# S32K116_M0P register map
Vendor: NXP Semiconductors; File version: 1.1
CPU: CM0PLUS r0p0, little endian, MPU, FPU, VTOR, 4 interrupt priority bits
Registers are 32-bit, read-write, reset 0x0 unless marked. A register's access mark holds for its fields unless they carry their own. Offsets are from the block's base; [hi:lo] are bit positions; {n}, {i} and the like mark numbered series; 'fields as' and 'values as' point back to an identical list.

## PMC
Base 0x4007D000
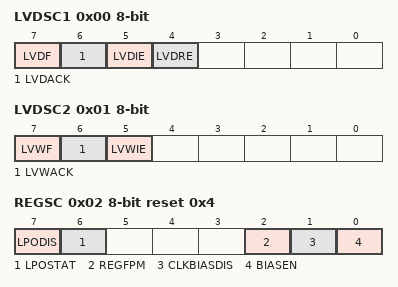
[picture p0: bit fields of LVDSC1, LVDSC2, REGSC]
0x00 LVDSC1 8-bit (reset mask 0xEF) — Low Voltage Detect Status and Control 1 Register
  [7] LVDF ro — Low Voltage Detect Flag
    0=Low-voltage event not detected; 1=Low-voltage event detected
  [6] LVDACK wo — Low Voltage Detect Acknowledge
  [5] LVDIE — Low Voltage Detect Interrupt Enable
    0=Hardware interrupt disabled (use polling); 1=Request a hardware interrupt when LVDF = 1
  [4] LVDRE — Low Voltage Detect Reset Enable
    0=No system resets on low voltage detect events; 1=If the supply voltage falls below VLVD, a system reset will be generated
0x01 LVDSC2 8-bit — Low Voltage Detect Status and Control 2 Register
  [7] LVWF ro — Low-Voltage Warning Flag
    0=Low-voltage warning event not detected; 1=Low-voltage warning event detected
  [6] LVWACK wo — Low-Voltage Warning Acknowledge
  [5] LVWIE — Low-Voltage Warning Interrupt Enable
    0=Hardware interrupt disabled (use polling); 1=Request a hardware interrupt when LVWF=1
0x02 REGSC 8-bit reset 0x4 (reset mask 0xBF) — Regulator Status and Control Register
  [7] LPODIS — LPO Disable Bit
    0=Low power oscillator enabled; 1=Low power oscillator disabled
  [6] LPOSTAT ro — LPO Status Bit
    0=Low power oscillator in low phase; 1=Low power oscillator in high phase
  [2] REGFPM ro — Regulator in Full Performance Mode Status Bit
    0=Regulator is in low power mode or transition to/from; 1=Regulator is in full performance mode
  [1] CLKBIASDIS — Clock Bias Disable Bit
    0=No effect; 1=In VLPS mode, the bias currents and reference voltages for the following clock modules are disabled: SIRC, FIRC, PLL. (if available on device)
  [0] BIASEN — Bias Enable Bit
    0=Biasing disabled, core logic can run in full performance; 1=Biasing enabled, core logic is slower and there are restrictions in allowed system clock speed (see Data Sheet for details)
0x04 LPOTRIM 8-bit (reset mask 0xE0) — Low Power Oscillator Trim Register
  [4:0] LPOTRIM — LPO trimming bits

## SMC — System Mode Controller
Base 0x4007E000; register names take the prefix SMC_
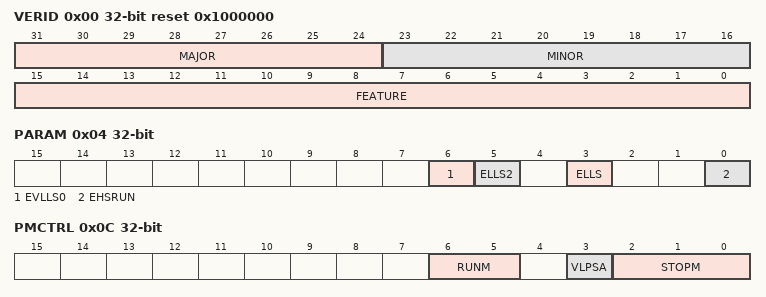
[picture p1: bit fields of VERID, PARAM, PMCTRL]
0x00 VERID ro reset 0x1000000 — SMC Version ID Register
  [31:24] MAJOR — Major Version Number
  [23:16] MINOR — Minor Version Number
  [15:0] FEATURE — Feature Specification Number
    0=Standard features implemented
0x04 PARAM ro — SMC Parameter Register
  [all] fields
    0=The feature is not available; 1=The feature is available
  [6] EVLLS0 — Existence of VLLS0 feature
  [5] ELLS2 — Existence of LLS2 feature
  [3] ELLS — Existence of LLS feature
  [0] EHSRUN — Existence of HSRUN feature
0x08 PMPROT — Power Mode Protection register
  [5] AVLP — Allow Very-Low-Power Modes
    0=VLPR and VLPS are not allowed; 1=VLPR and VLPS are allowed
0x0C PMCTRL — Power Mode Control register
  [6:5] RUNM — Run Mode Control
    0=Normal Run mode (RUN); 2=Very-Low-Power Run mode (VLPR)
  [3] VLPSA ro — Very Low Power Stop Aborted
    0=The previous stop mode entry was successful; 1=The previous stop mode entry was aborted
  [2:0] STOPM — Stop Mode Control
    0=Normal Stop (STOP); 2=Very-Low-Power Stop (VLPS); 6=Reseved
0x10 STOPCTRL reset 0x3 — Stop Control Register
  [7:6] STOPO — Stop Option
    1=STOP1 - Stop with both system and bus clocks disabled; 2=STOP2 - Stop with system clock disabled and bus clock enabled
0x14 PMSTAT ro reset 0x1 — Power Mode Status register
  [7:0] PMSTAT — Power Mode Status

## PTA — GPIO
Base 0x400FF000
Same registers: PTB 0x400FF040, PTC 0x400FF080, PTD 0x400FF0C0, PTE 0x400FF100
0x00 PDOR — Port Data Output Register
  [31:0] PDO — Port Data Output
0x04 PSOR — Port Set Output Register
  [31:0] PTSO — Port Set Output
0x08 PCOR — Port Clear Output Register
  [31:0] PTCO — Port Clear Output
0x0C PTOR — Port Toggle Output Register
  [31:0] PTTO — Port Toggle Output
0x10 PDIR ro — Port Data Input Register
  [31:0] PDI — Port Data Input
0x14 PDDR — Port Data Direction Register
  [31:0] PDD — Port Data Direction

## MTB_DWT — MTB data watchpoint and trace
Base 0xF0001000; register names take the prefix MTB_DWT_
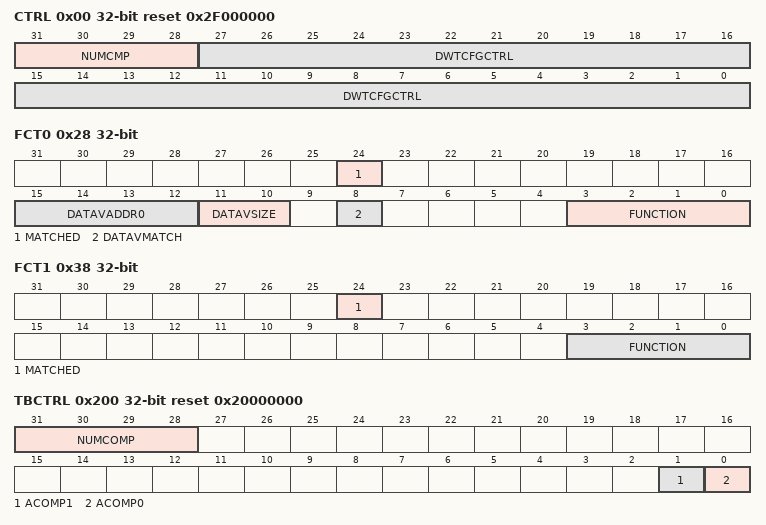
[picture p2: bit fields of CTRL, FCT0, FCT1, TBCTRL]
0x00 CTRL ro reset 0x2F000000 — MTB DWT Control Register
  [31:28] NUMCMP — Number of comparators
  [27:0] DWTCFGCTRL — DWT configuration controls
{0x20+0x10*i} COMP{i} (i=0..1) — MTB_DWT Comparator Register
  [31:0] COMP — Reference value for comparison
{0x24+0x10*i} MASK{i} (i=0..1) — MTB_DWT Comparator Mask Register
  [4:0] MASK
0x28 FCT0 — MTB_DWT Comparator Function Register 0
  [24] MATCHED ro — Comparator match
    0=No match; 1=Match occurred
  [15:12] DATAVADDR0 — Data Value Address 0
  [11:10] DATAVSIZE — Data Value Size
    0=Byte; 1=Halfword; 2=Word
  [8] DATAVMATCH — Data Value Match
    0=Perform address comparison; 1=Perform data value comparison
  [3:0] FUNCTION
    0=Disabled; 4=Instruction fetch; 5=Data operand read; 6=Data operand write; 7=Data operand (read + write)
0x38 FCT1 — MTB_DWT Comparator Function Register 1
  [24] MATCHED ro — Comparator match
    0=No match; 1=Match occurred
  [3:0] FUNCTION
    values as FCT0.FUNCTION
0x200 TBCTRL reset 0x20000000 — MTB_DWT Trace Buffer Control Register
  [31:28] NUMCOMP ro — Number of Comparators
  [1] ACOMP1 — Action based on Comparator 1 match
    0=Trigger TSTOP based on the assertion of MTBDWT_FCT1[MATCHED]; 1=Trigger TSTART based on the assertion of MTBDWT_FCT1[MATCHED]
  [0] ACOMP0 — Action based on Comparator 0 match
    0=Trigger TSTOP based on the assertion of MTBDWT_FCT0[MATCHED]; 1=Trigger TSTART based on the assertion of MTBDWT_FCT0[MATCHED]
0xFC8 DEVICECFG ro — Device Configuration Register
0xFCC DEVICETYPID ro reset 0x4 — Device Type Identifier Register
0xFD0 PERIPHID{x} (x=4,5,6,7,0,1,2,3; step 0x4) ro reset not defined — Peripheral ID Register
  [31:0] PERIPHID
{0xFF0+4i} COMPID{i} (i=0..3) ro reset not defined — Component ID Register
  [31:0] COMPID — Component ID
